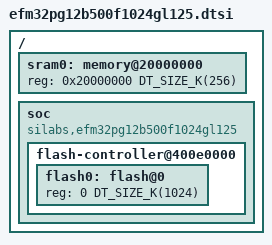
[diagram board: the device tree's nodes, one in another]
/*
 * Copyright (c) 2018 Linaro Limited
 *
 * SPDX-License-Identifier: Apache-2.0
 */

#include <mem.h>
#include <silabs/efm32pg12b.dtsi>

/ {
	sram0: memory@20000000 {
		reg = <0x20000000 DT_SIZE_K(256)>;
	};

	soc {
		compatible = "silabs,efm32pg12b500f1024gl125", "silabs,efm32pg12b", "silabs,efm32", "simple-bus";

		flash-controller@400e0000 {
			flash0: flash@0 {
				reg = <0 DT_SIZE_K(1024)>;
			};
		};
	};

};
